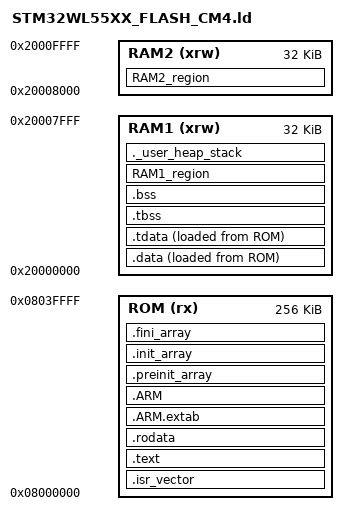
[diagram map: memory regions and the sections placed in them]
/*
** LinkerScript
** Note: For specific memory allocation, linker and startup files must be customized.
**       Refer to STM32CubeIDE user guide (UM2609), chapter "Modify the linker script".
*/

/* Entry Point */
ENTRY(Reset_Handler)


/* Memories definition */
MEMORY
{
  ROM    (rx)    : ORIGIN = 0x08000000, LENGTH = 256K
  RAM1   (xrw)   : ORIGIN = 0x20000000, LENGTH = 32K    /* Non-backup SRAM1 */
  RAM2   (xrw)   : ORIGIN = 0x20008000, LENGTH = 32K    /* Backup SRAM2 */
}
/* Highest address of the user mode stack */
_estack = ORIGIN(RAM1) + LENGTH(RAM1); /* end of "SRAM1" Ram type memory */

_Min_Heap_Size = 0x200;      /* required amount of heap  */
_Min_Stack_Size = 0x400; /* required amount of stack */

/* Sections */
SECTIONS
{
  /* The startup code into "ROM" Rom type memory */
  .isr_vector :
  {
    . = ALIGN(8);
    KEEP(*(.isr_vector)) /* Startup code */
    . = ALIGN(8);
  } >ROM

  /* The program code and other data into "ROM" Rom type memory */
  .text :
  {
    . = ALIGN(8);
    *(.text)           /* .text sections (code) */
    *(.text*)          /* .text* sections (code) */
    *(.glue_7)         /* glue arm to thumb code */
    *(.glue_7t)        /* glue thumb to arm code */
    *(.eh_frame)

    KEEP (*(.init))
    KEEP (*(.fini))

    . = ALIGN(8);
    _etext = .;        /* define a global symbols at end of code */
  } >ROM

  /* Constant data into "ROM" Rom type memory */
  .rodata :
  {
    . = ALIGN(8);
    *(.rodata)         /* .rodata sections (constants, strings, etc.) */
    *(.rodata*)        /* .rodata* sections (constants, strings, etc.) */
    . = ALIGN(8);
  } >ROM

  .ARM.extab (READONLY) : /* The READONLY keyword is only supported in GCC11 and later, remove it if using GCC10 or earlier. */
  {
    . = ALIGN(8);
    *(.ARM.extab* .gnu.linkonce.armextab.*)
    . = ALIGN(8);
  } >ROM
  
  .ARM (READONLY) : /* The READONLY keyword is only supported in GCC11 and later, remove it if using GCC10 or earlier. */
  {
    . = ALIGN(8);
    __exidx_start = .;
    *(.ARM.exidx*)
    __exidx_end = .;
    . = ALIGN(8);
  } >ROM

  .preinit_array (READONLY) : /* The READONLY keyword is only supported in GCC11 and later, remove it if using GCC10 or earlier. */
  {
    . = ALIGN(8);
    PROVIDE_HIDDEN (__preinit_array_start = .);
    KEEP (*(.preinit_array*))
    PROVIDE_HIDDEN (__preinit_array_end = .);
    . = ALIGN(8);
  } >ROM
  
  .init_array (READONLY) : /* The READONLY keyword is only supported in GCC11 and later, remove it if using GCC10 or earlier. */
  {
    . = ALIGN(8);
    PROVIDE_HIDDEN (__init_array_start = .);
    KEEP (*(SORT(.init_array.*)))
    KEEP (*(.init_array*))
    PROVIDE_HIDDEN (__init_array_end = .);
    . = ALIGN(8);
  } >ROM
  
  .fini_array (READONLY) : /* The READONLY keyword is only supported in GCC11 and later, remove it if using GCC10 or earlier. */
  {
    . = ALIGN(8);
    PROVIDE_HIDDEN (__fini_array_start = .);
    KEEP (*(SORT(.fini_array.*)))
    KEEP (*(.fini_array*))
    PROVIDE_HIDDEN (__fini_array_end = .);
    . = ALIGN(8);
  } >ROM

  /* Used by the startup to initialize data */
  _sidata = LOADADDR(.data);

  /* Initialized data sections into "SRAM1" Ram type memory */
  .data : 
  {
    . = ALIGN(8);
    _sdata = .;        /* create a global symbol at data start */
    *(.data)           /* .data sections */
    *(.data*)          /* .data* sections */

    . = ALIGN(8);
    
  } >RAM1 AT> ROM

  /* Initialized TLS data section */
  .tdata : ALIGN(4)
  {
    *(.tdata .tdata.* .gnu.linkonce.td.*)
    . = ALIGN(4);
    _edata = .;        /* define a global symbol at data end */
    PROVIDE(__data_end = .);
    PROVIDE(__tdata_end = .);
  } >RAM1 AT> ROM

  PROVIDE( __tdata_start = ADDR(.tdata) );
  PROVIDE( __tdata_size = __tdata_end - __tdata_start );

  PROVIDE( __data_start = ADDR(.data) );
  PROVIDE( __data_size = __data_end - __data_start );

  PROVIDE( __tdata_source = LOADADDR(.tdata) );
  PROVIDE( __tdata_source_end = LOADADDR(.tdata) + SIZEOF(.tdata) );
  PROVIDE( __tdata_source_size = __tdata_source_end - __tdata_source );

  PROVIDE( __data_source = LOADADDR(.data) );
  PROVIDE( __data_source_end = __tdata_source_end );
  PROVIDE( __data_source_size = __data_source_end - __data_source );


  /* Uninitialized data section into "SRAM1" Ram type memory */
  . = ALIGN(8);
  /* Uninitialized TLS data section */
  .tbss (NOLOAD) : ALIGN(4)
  {
    _sbss = .;         /* define a global symbol at bss start */
    __bss_start__ = _sbss;
    *(.tbss .tbss.*)
    . = ALIGN(4);
    PROVIDE( __tbss_end = . );
  } >RAM1

  PROVIDE( __tbss_start = ADDR(.tbss) );
  PROVIDE( __tbss_size = __tbss_end - __tbss_start );
  PROVIDE( __tbss_offset = ADDR(.tbss) - ADDR(.tdata) );

  PROVIDE( __tls_base = __tdata_start );
  PROVIDE( __tls_end = __tbss_end );
  PROVIDE( __tls_size = __tls_end - __tls_base );
  PROVIDE( __tls_align = MAX(ALIGNOF(.tdata), ALIGNOF(.tbss)) );
  PROVIDE( __tls_size_align = (__tls_size + __tls_align - 1) & ~(__tls_align - 1) );
  PROVIDE( __arm32_tls_tcb_offset = MAX(8, __tls_align) );
  PROVIDE( __arm64_tls_tcb_offset = MAX(16, __tls_align) );

  .bss (NOLOAD) : ALIGN(4)
  {
    /* This is used by the startup in order to initialize the .bss section */
    *(.bss)
    *(.bss*)
    *(COMMON)

    . = ALIGN(8);
      . = ALIGN(4);
    _ebss = .;         /* define a global symbol at bss end */
    __bss_end__ = _ebss;
      PROVIDE( __bss_end = .);
  } >RAM1
  PROVIDE( __non_tls_bss_start = ADDR(.bss) );

  PROVIDE( __bss_start = __tbss_start );
  PROVIDE( __bss_size = __bss_end - __bss_start );


  /* Data section into "SRAM1" Ram type memory: Non-backup SRAM1 dedicated to CM4 */
  . = ALIGN(8);
  RAM1_region :
  {
    _sRAM1_region = .;         /* define a global symbol at section start */
    *(.RAM1_region)

    . = ALIGN(8);
    _eRAM1_region = .;         /* define a global symbol at section end */
  } >RAM1

  /* Data section into "SRAM2" Ram type memory: Backup SRAM2 dedicated to CM4 */
  . = ALIGN(8);
  RAM2_region :
  {
    _sRAM2_region = .;         /* define a global symbol at section start */
    *(.RAM2_region)

    . = ALIGN(8);
    _eRAM2_region = .;         /* define a global symbol at section end */
  } >RAM2

  /* User_heap_stack section, used to check that there is enough "SRAM1" Ram  type memory left */
  ._user_heap_stack (NOLOAD) :
  {
    . = ALIGN(8);
    PROVIDE ( end = . );
    PROVIDE ( _end = . );
    . = . + _Min_Heap_Size;
    . = . + _Min_Stack_Size;
    . = ALIGN(8);
  } >RAM1

  /* Remove information from the compiler libraries */
  /DISCARD/ :
  {
    libc.a:* ( * )
    libm.a:* ( * )
    libgcc.a:* ( * )
  }

  .ARM.attributes 0 : { *(.ARM.attributes) }
}
